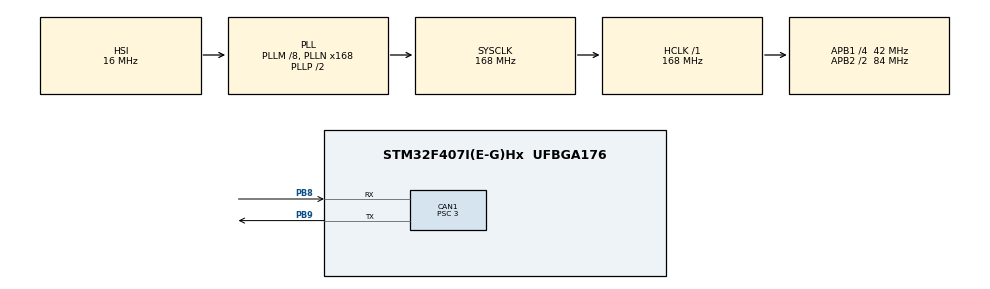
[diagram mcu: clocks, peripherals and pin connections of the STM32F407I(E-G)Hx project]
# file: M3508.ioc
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CAN1.BS1=CAN_BS1_10TQ
CAN1.BS2=CAN_BS2_3TQ
CAN1.CalculateBaudRate=1000000
CAN1.CalculateTimeBit=1000
CAN1.CalculateTimeQuantum=71.42857142857143
CAN1.Prescaler=3
Mcu.Family=STM32F4
Mcu.Name=STM32F407I(E-G)Hx
Mcu.Package=UFBGA176
NVIC.CAN1_RX0_IRQn=true\:0\:0\:false\:false\:true\:true\:true\:true
NVIC.PriorityGroup=NVIC_PRIORITYGROUP_4
PB8.Mode=CAN_Activate
PB8.Signal=CAN1_RX
PB9.Mode=CAN_Activate
PB9.Signal=CAN1_TX
ProjectManager.HeapSize=0x200
ProjectManager.StackSize=0x400
ProjectManager.TargetToolchain=MDK-ARM V5.32
RCC.48MHZClocksFreq_Value=84000000
RCC.AHBFreq_Value=168000000
RCC.APB1CLKDivider=RCC_HCLK_DIV4
RCC.APB1Freq_Value=42000000
RCC.APB1TimFreq_Value=84000000
RCC.APB2CLKDivider=RCC_HCLK_DIV2
RCC.APB2Freq_Value=84000000
RCC.APB2TimFreq_Value=168000000
RCC.CortexFreq_Value=168000000
RCC.HCLKFreq_Value=168000000
RCC.HSE_VALUE=25000000
RCC.HSI_VALUE=16000000
RCC.LSE_VALUE=32768
RCC.PLLM=8
RCC.PLLN=168
RCC.SYSCLKFreq_VALUE=168000000
RCC.SYSCLKSource=RCC_SYSCLKSOURCE_PLLCLK
RCC.VCOOutputFreq_Value=336000000
board=custom

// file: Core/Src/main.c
/* USER CODE BEGIN Header */
/**
  ******************************************************************************
  * @file           : main.c
  * @brief          : Main program body
  ******************************************************************************
  * @attention
  *
  * Copyright (c) 2025 STMicroelectronics.
  * All rights reserved.
  *
  * This software is licensed under terms that can be found in the LICENSE file
  * in the root directory of this software component.
  * If no LICENSE file comes with this software, it is provided AS-IS.
  *
  ******************************************************************************
  */
/* USER CODE END Header */
#include "main.h"
#include "can.h"
#include "gpio.h"

/* USER CODE BEGIN PV */
typedef struct {
    uint16_t ecd;          // 机械角度 (0~8191)
    int16_t  speed_rpm;    // 转速 (RPM)
    int16_t  given_current; // 实际转矩电流
    uint8_t  temperate;    // 温度
} motor_measure_t;

motor_measure_t motor_chassis[1]; // 定义 ID 为 1 的电机数据变量
/* USER CODE END PV */

void SystemClock_Config(void);

int main(void)
{

  /* MCU Configuration--------------------------------------------------------*/

  /* Reset of all peripherals, Initializes the Flash interface and the Systick. */
  HAL_Init();

  /* Configure the system clock */
  SystemClock_Config();

  /* Initialize all configured peripherals */
  MX_GPIO_Init();
  MX_CAN1_Init();
  /* USER CODE BEGIN 2 */
CAN_FilterTypeDef can_filter;

can_filter.FilterBank = 0;                       // 使用过滤器 0
can_filter.FilterMode = CAN_FILTERMODE_IDMASK;    // 掩码模式
can_filter.FilterScale = CAN_FILTERSCALE_32BIT;
can_filter.FilterIdHigh = 0x0000;                // 设置为 0 表示接收所有 ID
can_filter.FilterIdLow = 0x0000;
can_filter.FilterMaskIdHigh = 0x0000;
can_filter.FilterMaskIdLow = 0x0000;
can_filter.FilterFIFOAssignment = CAN_RX_FIFO0;  // 接收数据放入 FIFO0
can_filter.FilterActivation = ENABLE;            // 激活过滤器
can_filter.SlaveStartFilterBank = 14;

if (HAL_CAN_ConfigFilter(&hcan1, &can_filter) != HAL_OK) {
    Error_Handler();
}

HAL_CAN_Start(&hcan1); // 启动 CAN 外设
HAL_CAN_ActivateNotification(&hcan1, CAN_IT_RX_FIFO0_MSG_PENDING); // 开启接收中断
  /* USER CODE END 2 */

  /* Infinite loop */
  /* USER CODE BEGIN WHILE */
  while (1)
  {CAN_TxHeaderTypeDef tx_header;
    uint8_t tx_data[8];
    uint32_t pTxMailbox;

    // 设置发送报文头部
    tx_header.StdId = 0x200;      // M3508 ID 1-4 的控制标识符
    tx_header.IDE = CAN_ID_STD;   // 标准帧
    tx_header.RTR = CAN_RTR_DATA; // 数据帧
    tx_header.DLC = 8;            // 长度 8 字节

    // 设定电流：假设给 ID 1 电机发送 1000 的电流 (范围 -16384 到 16384)
    int16_t test_current = 1000;
    tx_data[0] = (test_current >> 8) & 0xFF; // 高 8 位
    tx_data[1] = test_current & 0xFF;        // 低 8 位

    // ID 2, 3, 4 的电流先设为 0
    tx_data[2] = tx_data[3] = tx_data[4] = tx_data[5] = tx_data[6] = tx_data[7] = 0;

    // 发送报文
    HAL_CAN_AddTxMessage(&hcan1, &tx_header, tx_data, &pTxMailbox);

    HAL_Delay(10); // 间隔 10ms 发送一次
    /* USER CODE END WHILE */

  }
}

void SystemClock_Config(void)
{
  RCC_OscInitTypeDef RCC_OscInitStruct = {0};
  RCC_ClkInitTypeDef RCC_ClkInitStruct = {0};

  /** Configure the main internal regulator output voltage
  */
  __HAL_RCC_PWR_CLK_ENABLE();
  __HAL_PWR_VOLTAGESCALING_CONFIG(PWR_REGULATOR_VOLTAGE_SCALE1);

  /** Initializes the RCC Oscillators according to the specified parameters
  * in the RCC_OscInitTypeDef structure.
  */
  RCC_OscInitStruct.OscillatorType = RCC_OSCILLATORTYPE_HSI;
  RCC_OscInitStruct.HSIState = RCC_HSI_ON;
  RCC_OscInitStruct.HSICalibrationValue = RCC_HSICALIBRATION_DEFAULT;
  RCC_OscInitStruct.PLL.PLLState = RCC_PLL_ON;
  RCC_OscInitStruct.PLL.PLLSource = RCC_PLLSOURCE_HSI;
  RCC_OscInitStruct.PLL.PLLM = 8;
  RCC_OscInitStruct.PLL.PLLN = 168;
  RCC_OscInitStruct.PLL.PLLP = RCC_PLLP_DIV2;
  RCC_OscInitStruct.PLL.PLLQ = 4;
  if (HAL_RCC_OscConfig(&RCC_OscInitStruct) != HAL_OK)
  {
    Error_Handler();
  }

  /** Initializes the CPU, AHB and APB buses clocks
  */
  RCC_ClkInitStruct.ClockType = RCC_CLOCKTYPE_HCLK|RCC_CLOCKTYPE_SYSCLK
                              |RCC_CLOCKTYPE_PCLK1|RCC_CLOCKTYPE_PCLK2;
  RCC_ClkInitStruct.SYSCLKSource = RCC_SYSCLKSOURCE_PLLCLK;
  RCC_ClkInitStruct.AHBCLKDivider = RCC_SYSCLK_DIV1;
  RCC_ClkInitStruct.APB1CLKDivider = RCC_HCLK_DIV4;
  RCC_ClkInitStruct.APB2CLKDivider = RCC_HCLK_DIV2;

  if (HAL_RCC_ClockConfig(&RCC_ClkInitStruct, FLASH_LATENCY_5) != HAL_OK)
  {
    Error_Handler();
  }
}

/* USER CODE BEGIN 4 */
void HAL_CAN_RxFifo0MsgPendingCallback(CAN_HandleTypeDef *hcan) {
    CAN_RxHeaderTypeDef rx_header;
    uint8_t rx_data[8];

    if (HAL_CAN_GetRxMessage(hcan, CAN_RX_FIFO0, &rx_header, rx_data) == HAL_OK) {
        // ID 1 电机的反馈报文 ID 是 0x201
        if (rx_header.StdId == 0x201) {
            motor_chassis[0].ecd = (rx_data[0] << 8) | rx_data[1];
            motor_chassis[0].speed_rpm = (int16_t)(rx_data[2] << 8 | rx_data[3]);
            motor_chassis[0].given_current = (int16_t)(rx_data[4] << 8 | rx_data[5]);
            motor_chassis[0].temperate = rx_data[6];
        }
    }
}
/* USER CODE END 4 */

void Error_Handler(void)
{
  __disable_irq();
  while (1)
  {
  }
}
